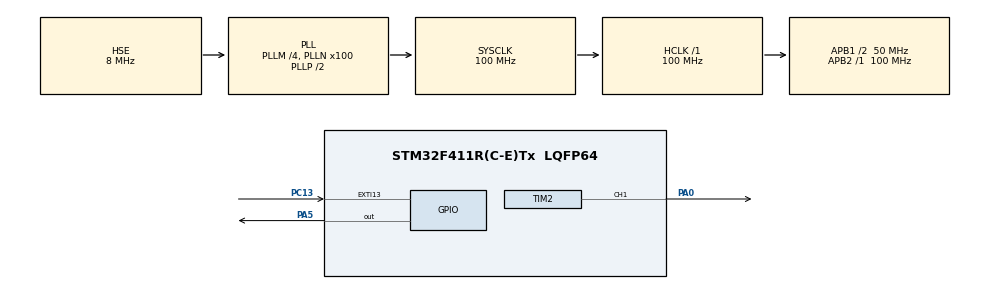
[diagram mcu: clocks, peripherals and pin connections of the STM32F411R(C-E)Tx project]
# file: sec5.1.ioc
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Mcu.Family=STM32F4
RCC.PLLSourceVirtual=RCC_PLLSOURCE_HSE
RCC.CortexFreq_Value=100000000
TIM2.OCMode_PWM-PWM\ Generation1\ CH1=TIM_OCMODE_PWM1
PH1\ -\ OSC_OUT.Mode=HSE-External-Clock-Source
RCC.APB1CLKDivider=RCC_HCLK_DIV2
RCC.SYSCLKSource=RCC_SYSCLKSOURCE_PLLCLK
ProjectManager.StackSize=0x400
PA0-WKUP.Signal=S_TIM2_CH1_ETR
TIM2.Pulse-PWM\ Generation1\ CH1=140000
PA13.Signal=SYS_JTMS-SWDIO
PH0\ -\ OSC_IN.Mode=HSE-External-Clock-Source
PH0\ -\ OSC_IN.Signal=RCC_OSC_IN
ProjectManager.TargetToolchain=STM32CubeIDE
RCC.HCLKFreq_Value=100000000
RCC.APB2TimFreq_Value=100000000
RCC.LSE_VALUE=32768
RCC.AHBFreq_Value=100000000
NVIC.EXTI15_10_IRQn=true\:0\:0\:false\:false\:true\:true\:true
PA5.Signal=GPIO_Output
RCC.HSE_VALUE=8000000
PH1\ -\ OSC_OUT.Signal=RCC_OSC_OUT
board=custom
PC13-ANTI_TAMP.Signal=GPXTI13
RCC.VCOOutputFreq_Value=200000000
RCC.APB2Freq_Value=100000000
VP_TIM2_VS_ClockSourceINT.Mode=Internal
PA14.Mode=Serial_Wire
NVIC.TIM2_IRQn=true\:1\:0\:true\:false\:true\:true\:true
TIM2.Channel-PWM\ Generation1\ CH1=TIM_CHANNEL_1
TIM2.Period=200000-1
PA13.Mode=Serial_Wire
Mcu.Name=STM32F411R(C-E)Tx
RCC.48MHZClocksFreq_Value=50000000
RCC.SYSCLKFreq_VALUE=100000000
Mcu.Package=LQFP64
TIM2.Prescaler=9999
PC13-ANTI_TAMP.GPIO_ModeDefaultEXTI=GPIO_MODE_IT_FALLING
SH.S_TIM2_CH1_ETR.0=TIM2_CH1,PWM Generation1 CH1
PA14.Signal=SYS_JTCK-SWCLK
ProjectManager.HeapSize=0x200
RCC.HSI_VALUE=16000000
NVIC.PriorityGroup=NVIC_PRIORITYGROUP_1
RCC.PLLM=4
RCC.PLLN=100
RCC.APB1TimFreq_Value=100000000
RCC.APB1Freq_Value=50000000

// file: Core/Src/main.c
/* USER CODE BEGIN Header */
/**
  ******************************************************************************
  * @file           : main.c
  * @brief          : Main program body
  ******************************************************************************
  * @attention
  *
  * <h2><center>&copy; Copyright (c) 2021 STMicroelectronics.
  * All rights reserved.</center></h2>
  *
  * This software component is licensed by ST under BSD 3-Clause license,
  * the "License"; You may not use this file except in compliance with the
  * License. You may obtain a copy of the License at:
  *                        opensource.org/licenses/BSD-3-Clause
  *
  ******************************************************************************
  */
/* USER CODE END Header */
#include "main.h"

TIM_HandleTypeDef htim2;

/* USER CODE BEGIN PV */
uint8_t Flag = 0;
uint8_t EXITFlag = 0;

/* USER CODE END PV */

void SystemClock_Config(void);
static void MX_GPIO_Init(void);
static void MX_TIM2_Init(void);
/* USER CODE BEGIN PFP */
void MORSE_CODE();
/* USER CODE END PFP */

int main(void)
{

  /* MCU Configuration--------------------------------------------------------*/

  /* Reset of all peripherals, Initializes the Flash interface and the Systick. */
  HAL_Init();

  /* Configure the system clock */
  SystemClock_Config();

  /* Initialize all configured peripherals */
  MX_GPIO_Init();
  MX_TIM2_Init();
  /* USER CODE BEGIN 2 */
  __HAL_TIM_CLEAR_IT(&htim2, TIM_IT_UPDATE);
  HAL_TIM_Base_Start_IT(&htim2);
  HAL_TIM_PWM_Start_IT(&htim2, TIM_CHANNEL_1);
  /* USER CODE END 2 */

  /* Infinite loop */
  while (1)
  {

    /* USER CODE BEGIN 3 */
	  if (Flag == 0)
	  {
		  blink:
		  MORSE_CODE();
		  if (EXITFlag == 1)
		  {
			  EXITFlag = 0;
			  HAL_Delay(3000);
			  goto blink;
		  }
	  }
	  else
		  HAL_GPIO_WritePin(GPIOA,GPIO_PIN_5,0);
  }
  /* USER CODE END 3 */
}

void SystemClock_Config(void)
{
  RCC_OscInitTypeDef RCC_OscInitStruct = {0};
  RCC_ClkInitTypeDef RCC_ClkInitStruct = {0};

  /** Configure the main internal regulator output voltage
  */
  __HAL_RCC_PWR_CLK_ENABLE();
  __HAL_PWR_VOLTAGESCALING_CONFIG(PWR_REGULATOR_VOLTAGE_SCALE1);
  /** Initializes the RCC Oscillators according to the specified parameters
  * in the RCC_OscInitTypeDef structure.
  */
  RCC_OscInitStruct.OscillatorType = RCC_OSCILLATORTYPE_HSE;
  RCC_OscInitStruct.HSEState = RCC_HSE_BYPASS;
  RCC_OscInitStruct.PLL.PLLState = RCC_PLL_ON;
  RCC_OscInitStruct.PLL.PLLSource = RCC_PLLSOURCE_HSE;
  RCC_OscInitStruct.PLL.PLLM = 4;
  RCC_OscInitStruct.PLL.PLLN = 100;
  RCC_OscInitStruct.PLL.PLLP = RCC_PLLP_DIV2;
  RCC_OscInitStruct.PLL.PLLQ = 4;
  if (HAL_RCC_OscConfig(&RCC_OscInitStruct) != HAL_OK)
  {
    Error_Handler();
  }
  /** Initializes the CPU, AHB and APB buses clocks
  */
  RCC_ClkInitStruct.ClockType = RCC_CLOCKTYPE_HCLK|RCC_CLOCKTYPE_SYSCLK
                              |RCC_CLOCKTYPE_PCLK1|RCC_CLOCKTYPE_PCLK2;
  RCC_ClkInitStruct.SYSCLKSource = RCC_SYSCLKSOURCE_PLLCLK;
  RCC_ClkInitStruct.AHBCLKDivider = RCC_SYSCLK_DIV1;
  RCC_ClkInitStruct.APB1CLKDivider = RCC_HCLK_DIV2;
  RCC_ClkInitStruct.APB2CLKDivider = RCC_HCLK_DIV1;

  if (HAL_RCC_ClockConfig(&RCC_ClkInitStruct, FLASH_LATENCY_3) != HAL_OK)
  {
    Error_Handler();
  }
}

static void MX_TIM2_Init(void)
{

  TIM_ClockConfigTypeDef sClockSourceConfig = {0};
  TIM_MasterConfigTypeDef sMasterConfig = {0};
  TIM_OC_InitTypeDef sConfigOC = {0};

  htim2.Instance = TIM2;
  htim2.Init.Prescaler = 9999;
  htim2.Init.CounterMode = TIM_COUNTERMODE_UP;
  htim2.Init.Period = 200000-1;
  htim2.Init.ClockDivision = TIM_CLOCKDIVISION_DIV1;
  htim2.Init.AutoReloadPreload = TIM_AUTORELOAD_PRELOAD_DISABLE;
  if (HAL_TIM_Base_Init(&htim2) != HAL_OK)
  {
    Error_Handler();
  }
  sClockSourceConfig.ClockSource = TIM_CLOCKSOURCE_INTERNAL;
  if (HAL_TIM_ConfigClockSource(&htim2, &sClockSourceConfig) != HAL_OK)
  {
    Error_Handler();
  }
  if (HAL_TIM_PWM_Init(&htim2) != HAL_OK)
  {
    Error_Handler();
  }
  sMasterConfig.MasterOutputTrigger = TIM_TRGO_RESET;
  sMasterConfig.MasterSlaveMode = TIM_MASTERSLAVEMODE_DISABLE;
  if (HAL_TIMEx_MasterConfigSynchronization(&htim2, &sMasterConfig) != HAL_OK)
  {
    Error_Handler();
  }
  sConfigOC.OCMode = TIM_OCMODE_PWM1;
  sConfigOC.Pulse = 140000;
  sConfigOC.OCPolarity = TIM_OCPOLARITY_HIGH;
  sConfigOC.OCFastMode = TIM_OCFAST_DISABLE;
  if (HAL_TIM_PWM_ConfigChannel(&htim2, &sConfigOC, TIM_CHANNEL_1) != HAL_OK)
  {
    Error_Handler();
  }
  HAL_TIM_MspPostInit(&htim2);

}

static void MX_GPIO_Init(void)
{
  GPIO_InitTypeDef GPIO_InitStruct = {0};

  /* GPIO Ports Clock Enable */
  __HAL_RCC_GPIOC_CLK_ENABLE();
  __HAL_RCC_GPIOH_CLK_ENABLE();
  __HAL_RCC_GPIOA_CLK_ENABLE();

  /*Configure GPIO pin Output Level */
  HAL_GPIO_WritePin(GPIOA, GPIO_PIN_5, GPIO_PIN_RESET);

  /*Configure GPIO pin : PC13 */
  GPIO_InitStruct.Pin = GPIO_PIN_13;
  GPIO_InitStruct.Mode = GPIO_MODE_IT_FALLING;
  GPIO_InitStruct.Pull = GPIO_NOPULL;
  HAL_GPIO_Init(GPIOC, &GPIO_InitStruct);

  /*Configure GPIO pin : PA5 */
  GPIO_InitStruct.Pin = GPIO_PIN_5;
  GPIO_InitStruct.Mode = GPIO_MODE_OUTPUT_PP;
  GPIO_InitStruct.Pull = GPIO_NOPULL;
  GPIO_InitStruct.Speed = GPIO_SPEED_FREQ_LOW;
  HAL_GPIO_Init(GPIOA, &GPIO_InitStruct);

  /* EXTI interrupt init*/
  HAL_NVIC_SetPriority(EXTI15_10_IRQn, 0, 0);
  HAL_NVIC_EnableIRQ(EXTI15_10_IRQn);

}

/* USER CODE BEGIN 4 */
void HAL_TIM_PWM_PulseFinishedCallback (TIM_HandleTypeDef * htim)
{
	if (htim->Instance == TIM2)
	{
		if (htim->Channel == HAL_TIM_ACTIVE_CHANNEL_1)
		{
			Flag = 1;
		}
	}

}

void HAL_TIM_PeriodElapsedCallback (TIM_HandleTypeDef * htim)
{
	if (htim->Instance == TIM2)
		Flag = 0;

}

void HAL_GPIO_EXTI_Callback(uint16_t GPIO_Pin)
{
  /* EXTI line interrupt detected */
  if(HAL_GPIO_ReadPin(GPIOC,GPIO_PIN_13) == 0)
  {
	  EXITFlag = 1;
	  HAL_GPIO_WritePin(GPIOA,GPIO_PIN_5,0);
  }
}

void MORSE_CODE()
{
HAL_GPIO_WritePin(GPIOA,GPIO_PIN_5,1);
HAL_Delay(300);
if (EXITFlag || Flag)
	return;
HAL_GPIO_WritePin(GPIOA,GPIO_PIN_5,0);
HAL_Delay(300);
if (EXITFlag|| Flag)
	return;
HAL_GPIO_WritePin(GPIOA,GPIO_PIN_5,1);
HAL_Delay(300);
if (EXITFlag|| Flag)
	return;
HAL_GPIO_WritePin(GPIOA,GPIO_PIN_5,0);
HAL_Delay(300);
if (EXITFlag|| Flag)
	return;
HAL_GPIO_WritePin(GPIOA,GPIO_PIN_5,1);
HAL_Delay(300);
if (EXITFlag|| Flag)
	return;
HAL_GPIO_WritePin(GPIOA,GPIO_PIN_5,0);
HAL_Delay(300);
if (EXITFlag|| Flag)
	return;

HAL_GPIO_WritePin(GPIOA,GPIO_PIN_5,0);
HAL_Delay(600);
if (EXITFlag|| Flag)
	return;

HAL_GPIO_WritePin(GPIOA,GPIO_PIN_5,1);
HAL_Delay(900);
if (EXITFlag|| Flag)
	return;
HAL_GPIO_WritePin(GPIOA,GPIO_PIN_5,0);
HAL_Delay(300);
if (EXITFlag|| Flag)
	return;
HAL_GPIO_WritePin(GPIOA,GPIO_PIN_5,1);
HAL_Delay(900);
if (EXITFlag|| Flag)
	return;
HAL_GPIO_WritePin(GPIOA,GPIO_PIN_5,0);
HAL_Delay(300);
if (EXITFlag|| Flag)
	return;
HAL_GPIO_WritePin(GPIOA,GPIO_PIN_5,1);
HAL_Delay(900);
if (EXITFlag|| Flag)
	return;
HAL_GPIO_WritePin(GPIOA,GPIO_PIN_5,0);
HAL_Delay(300);
if (EXITFlag|| Flag)
	return;

HAL_GPIO_WritePin(GPIOA,GPIO_PIN_5,0);
HAL_Delay(600);
if (EXITFlag|| Flag)
	return;

HAL_GPIO_WritePin(GPIOA,GPIO_PIN_5,1);
HAL_Delay(300);
if (EXITFlag|| Flag)
	return;
HAL_GPIO_WritePin(GPIOA,GPIO_PIN_5,0);
HAL_Delay(300);
if (EXITFlag|| Flag)
	return;
HAL_GPIO_WritePin(GPIOA,GPIO_PIN_5,1);
HAL_Delay(300);
if (EXITFlag|| Flag)
	return;
HAL_GPIO_WritePin(GPIOA,GPIO_PIN_5,0);
HAL_Delay(300);
if (EXITFlag|| Flag)
	return;
HAL_GPIO_WritePin(GPIOA,GPIO_PIN_5,1);
HAL_Delay(300);
if (EXITFlag|| Flag)
	return;
HAL_GPIO_WritePin(GPIOA,GPIO_PIN_5,0);
HAL_Delay(300);
if (EXITFlag|| Flag)
	return;

HAL_GPIO_WritePin(GPIOA,GPIO_PIN_5,0);
HAL_Delay(600);
}

/* USER CODE END 4 */

void Error_Handler(void)
{
  __disable_irq();
  while (1)
  {
  }
}

/************************ (C) COPYRIGHT STMicroelectronics *****END OF FILE****/
